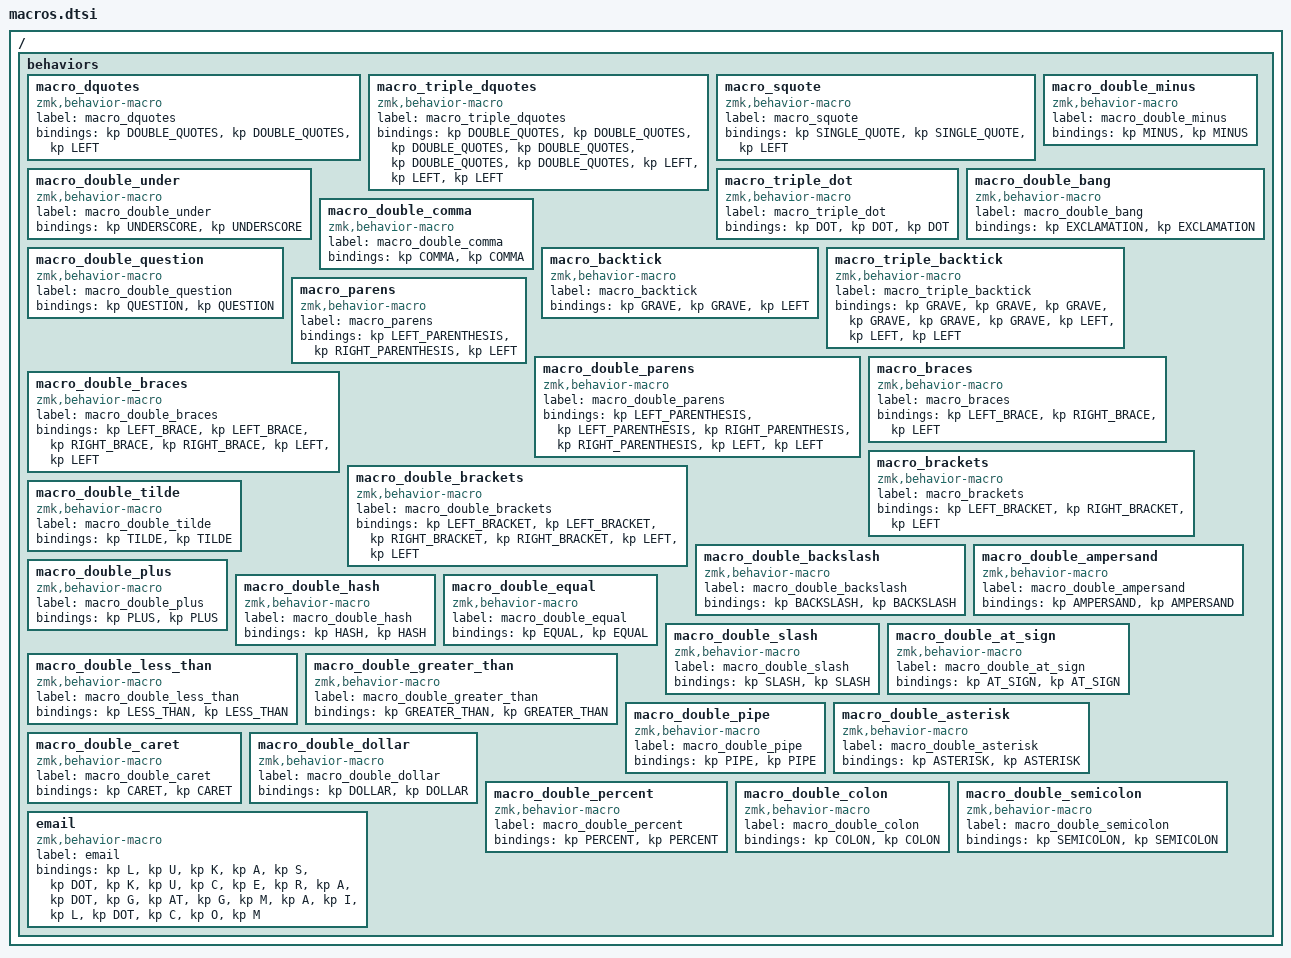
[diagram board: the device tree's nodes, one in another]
// Copyright 2022 Lukas Kucera
// https://github.com/kucera-lukas/zmk-config

#include <behaviors.dtsi>
#include <dt-bindings/zmk/keys.h>

#include "hold_tap.h"
#include "mod_morph.h"

#include "hold_tap.dtsi"
#include "mod_morph.dtsi"

/ {
  behaviors {
    macro_dquotes: macro_dquotes {
      compatible = "zmk,behavior-macro";
      label = "macro_dquotes";
      #binding-cells = <0>;
      bindings = <&kp DOUBLE_QUOTES &kp DOUBLE_QUOTES &kp LEFT>;
    };

    macro_triple_dquotes: macro_triple_dquotes {
      compatible = "zmk,behavior-macro";
      label = "macro_triple_dquotes";
      #binding-cells = <0>;
      bindings = <&kp DOUBLE_QUOTES &kp DOUBLE_QUOTES &kp DOUBLE_QUOTES &kp DOUBLE_QUOTES &kp DOUBLE_QUOTES &kp DOUBLE_QUOTES &kp LEFT &kp LEFT &kp LEFT>;
    };

    macro_squote: macro_squote {
      compatible = "zmk,behavior-macro";
      label = "macro_squote";
      #binding-cells = <0>;
      bindings = <&kp SINGLE_QUOTE &kp SINGLE_QUOTE &kp LEFT>;
    };

    macro_double_under: macro_double_under {
      compatible = "zmk,behavior-macro";
      label = "macro_double_under";
      #binding-cells = <0>;
      bindings = <&kp UNDERSCORE &kp UNDERSCORE>;
    };

    macro_double_minus: macro_double_minus {
      compatible = "zmk,behavior-macro";
      label = "macro_double_minus";
      #binding-cells = <0>;
      bindings = <&kp MINUS &kp MINUS>;
    };

    macro_triple_dot: macro_triple_dot {
      compatible = "zmk,behavior-macro";
      label = "macro_triple_dot";
      #binding-cells = <0>;
      bindings = <&kp DOT &kp DOT &kp DOT>;
    };

    macro_double_bang: macro_double_bang {
      compatible = "zmk,behavior-macro";
      label = "macro_double_bang";
      #binding-cells = <0>;
      bindings = <&kp EXCLAMATION &kp EXCLAMATION>;
    };

    macro_double_comma: macro_double_comma {
      compatible = "zmk,behavior-macro";
      label = "macro_double_comma";
      #binding-cells = <0>;
      bindings = <&kp COMMA &kp COMMA>;
    };

    macro_double_question: macro_double_question {
      compatible = "zmk,behavior-macro";
      label = "macro_double_question";
      #binding-cells = <0>;
      bindings = <&kp QUESTION &kp QUESTION>;
    };

    macro_backtick: macro_backtick {
      compatible = "zmk,behavior-macro";
      label = "macro_backtick";
      #binding-cells = <0>;
      bindings = <&kp GRAVE &kp GRAVE &kp LEFT>;
    };

    macro_triple_backtick: macro_triple_backtick {
      compatible = "zmk,behavior-macro";
      label = "macro_triple_backtick";
      #binding-cells = <0>;
      bindings = <&kp GRAVE &kp GRAVE &kp GRAVE &kp GRAVE &kp GRAVE &kp GRAVE &kp LEFT &kp LEFT &kp LEFT>;
    };

    macro_parens: macro_parens {
      compatible = "zmk,behavior-macro";
      label = "macro_parens";
      #binding-cells = <0>;
      bindings = <&kp LEFT_PARENTHESIS &kp RIGHT_PARENTHESIS &kp LEFT>;
    };

    macro_double_parens: macro_double_parens {
      compatible = "zmk,behavior-macro";
      label = "macro_double_parens";
      #binding-cells = <0>;
      bindings = <&kp LEFT_PARENTHESIS &kp LEFT_PARENTHESIS &kp RIGHT_PARENTHESIS &kp RIGHT_PARENTHESIS &kp LEFT &kp LEFT>;
    };

    macro_braces: macro_braces {
      compatible = "zmk,behavior-macro";
      label = "macro_braces";
      #binding-cells = <0>;
      bindings = <&kp LEFT_BRACE &kp RIGHT_BRACE &kp LEFT>;
    };

    macro_double_braces: macro_double_braces {
      compatible = "zmk,behavior-macro";
      label = "macro_double_braces";
      #binding-cells = <0>;
      bindings = <&kp LEFT_BRACE &kp LEFT_BRACE &kp RIGHT_BRACE &kp RIGHT_BRACE &kp LEFT &kp LEFT>;
    };

    macro_brackets: macro_brackets {
      compatible = "zmk,behavior-macro";
      label = "macro_brackets";
      #binding-cells = <0>;
      bindings = <&kp LEFT_BRACKET &kp RIGHT_BRACKET &kp LEFT>;
    };

    macro_double_brackets: macro_double_brackets {
      compatible = "zmk,behavior-macro";
      label = "macro_double_brackets";
      #binding-cells = <0>;
      bindings = <&kp LEFT_BRACKET &kp LEFT_BRACKET &kp RIGHT_BRACKET &kp RIGHT_BRACKET &kp LEFT &kp LEFT>;
    };

    macro_double_tilde: macro_double_tilde {
      compatible = "zmk,behavior-macro";
      label = "macro_double_tilde";
      #binding-cells = <0>;
      bindings = <&kp TILDE &kp TILDE>;
    };

    macro_double_backslash: macro_double_backslash {
      compatible = "zmk,behavior-macro";
      label = "macro_double_backslash";
      #binding-cells = <0>;
      bindings = <&kp BACKSLASH &kp BACKSLASH>;
    };

    macro_double_ampersand: macro_double_ampersand {
      compatible = "zmk,behavior-macro";
      label = "macro_double_ampersand";
      #binding-cells = <0>;
      bindings = <&kp AMPERSAND &kp AMPERSAND>;
    };

    macro_double_plus: macro_double_plus {
      compatible = "zmk,behavior-macro";
      label = "macro_double_plus";
      #binding-cells = <0>;
      bindings = <&kp PLUS &kp PLUS>;
    };

    macro_double_hash: macro_double_hash {
      compatible = "zmk,behavior-macro";
      label = "macro_double_hash";
      #binding-cells = <0>;
      bindings = <&kp HASH &kp HASH>;
    };

    macro_double_equal: macro_double_equal {
      compatible = "zmk,behavior-macro";
      label = "macro_double_equal";
      #binding-cells = <0>;
      bindings = <&kp EQUAL &kp EQUAL>;
    };

    macro_double_slash: macro_double_slash {
      compatible = "zmk,behavior-macro";
      label = "macro_double_slash";
      #binding-cells = <0>;
      bindings = <&kp SLASH &kp SLASH>;
    };

    macro_double_at_sign: macro_double_at_sign {
      compatible = "zmk,behavior-macro";
      label = "macro_double_at_sign";
      #binding-cells = <0>;
      bindings = <&kp AT_SIGN &kp AT_SIGN>;
    };

    macro_double_less_than: macro_double_less_than {
      compatible = "zmk,behavior-macro";
      label = "macro_double_less_than";
      #binding-cells = <0>;
      bindings = <&kp LESS_THAN &kp LESS_THAN>;
    };

    macro_double_greater_than: macro_double_greater_than {
      compatible = "zmk,behavior-macro";
      label = "macro_double_greater_than";
      #binding-cells = <0>;
      bindings = <&kp GREATER_THAN &kp GREATER_THAN>;
    };

    macro_double_pipe: macro_double_pipe {
      compatible = "zmk,behavior-macro";
      label = "macro_double_pipe";
      #binding-cells = <0>;
      bindings = <&kp PIPE &kp PIPE>;
    };

    macro_double_asterisk: macro_double_asterisk {
      compatible = "zmk,behavior-macro";
      label = "macro_double_asterisk";
      #binding-cells = <0>;
      bindings = <&kp ASTERISK &kp ASTERISK>;
    };

    macro_double_caret: macro_double_caret {
      compatible = "zmk,behavior-macro";
      label = "macro_double_caret";
      #binding-cells = <0>;
      bindings = <&kp CARET &kp CARET>;
    };

    macro_double_dollar: macro_double_dollar {
      compatible = "zmk,behavior-macro";
      label = "macro_double_dollar";
      #binding-cells = <0>;
      bindings = <&kp DOLLAR &kp DOLLAR>;
    };

    macro_double_percent: macro_double_percent {
      compatible = "zmk,behavior-macro";
      label = "macro_double_percent";
      #binding-cells = <0>;
      bindings = <&kp PERCENT &kp PERCENT>;
    };

    macro_double_colon: macro_double_colon {
      compatible = "zmk,behavior-macro";
      label = "macro_double_colon";
      #binding-cells = <0>;
      bindings = <&kp COLON &kp COLON>;
    };

    macro_double_semicolon: macro_double_semicolon {
      compatible = "zmk,behavior-macro";
      label = "macro_double_semicolon";
      #binding-cells = <0>;
      bindings = <&kp SEMICOLON &kp SEMICOLON>;
    };

    email: email {
      compatible = "zmk,behavior-macro";
      label = "email";
      #binding-cells = <0>;
      bindings
        = <&kp L &kp U &kp K &kp A &kp S>
        , <&kp DOT>
        , <&kp K &kp U &kp C &kp E &kp R &kp A>
        , <&kp DOT>
        , <&kp G>
        , <&kp AT>
        , <&kp G &kp M &kp A &kp I &kp L>
        , <&kp DOT>
        , <&kp C &kp O &kp M>
        ;
    };
  };
};

HOLD_TAP_FUNCTION(single_triple_dquotes, &macro_triple_dquotes, &macro_dquotes)
HOLD_TAP_KP_FUNCTION(one_two_squotes, &macro_squote)
SHIFT_FUNCTION(dquotes_squotes, &single_triple_dquotes 0 0, &one_two_squotes 0 SINGLE_QUOTE)

HOLD_TAP_KP_FUNCTION(single_double_under, &macro_double_under)
HOLD_TAP_KP_FUNCTION(single_double_minus, &macro_double_minus)
SHIFT_FUNCTION(under_minus, &single_double_under 0 UNDERSCORE, &single_double_minus 0 MINUS)

HOLD_TAP_KP_FUNCTION(single_triple_dot, &macro_triple_dot)
HOLD_TAP_KP_FUNCTION(single_double_bang, &macro_double_bang)
SHIFT_FUNCTION(dot_bang, &single_triple_dot 0 DOT, &single_double_bang 0 EXCLAMATION)

HOLD_TAP_KP_FUNCTION(single_double_comma, &macro_double_comma)
HOLD_TAP_KP_FUNCTION(single_double_question, &macro_double_question)
SHIFT_FUNCTION(comma_question, &single_double_comma 0 COMMA, &single_double_question 0 QUESTION)

HOLD_TAP_FUNCTION(single_triple_backtick, &macro_triple_backtick, &macro_backtick)
HOLD_TAP_FUNCTION(single_double_parens, &macro_double_parens, &macro_parens)
HOLD_TAP_FUNCTION(single_double_braces, &macro_double_braces, &macro_braces)
HOLD_TAP_FUNCTION(single_double_brackets, &macro_double_brackets, &macro_brackets)

HOLD_TAP_KP_FUNCTION(single_double_semicolon, &macro_double_semicolon)
HOLD_TAP_KP_FUNCTION(single_double_semicolon, &macro_double_semicolon)
HOLD_TAP_KP_FUNCTION(single_double_tilde, &macro_double_tilde)
HOLD_TAP_KP_FUNCTION(single_double_backslash, &macro_double_backslash)
HOLD_TAP_KP_FUNCTION(single_double_ampersand, &macro_double_ampersand)
HOLD_TAP_KP_FUNCTION(single_double_plus, &macro_double_plus)
HOLD_TAP_KP_FUNCTION(single_double_hash, &macro_double_hash)
HOLD_TAP_KP_FUNCTION(single_double_equal, &macro_double_equal)
HOLD_TAP_KP_FUNCTION(single_double_slash, &macro_double_slash)
HOLD_TAP_KP_FUNCTION(single_double_at_sign, &macro_double_at_sign)
HOLD_TAP_KP_FUNCTION(single_double_less_than, &macro_double_less_than)
HOLD_TAP_KP_FUNCTION(single_double_greater_than, &macro_double_greater_than)
HOLD_TAP_KP_FUNCTION(single_double_pipe, &macro_double_pipe)
HOLD_TAP_KP_FUNCTION(single_double_asterisk, &macro_double_asterisk)
HOLD_TAP_KP_FUNCTION(single_double_caret, &macro_double_caret)
HOLD_TAP_KP_FUNCTION(single_double_dollar, &macro_double_dollar)
HOLD_TAP_KP_FUNCTION(single_double_percent, &macro_double_percent)
HOLD_TAP_KP_FUNCTION(single_double_colon, &macro_double_colon)
HOLD_TAP_KP_FUNCTION(single_double_semicolon, &macro_double_semicolon)
